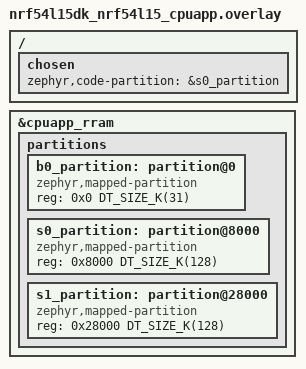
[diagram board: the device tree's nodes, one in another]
/*
 * Copyright (c) 2026 Nordic Semiconductor ASA
 *
 * SPDX-License-Identifier: LicenseRef-Nordic-5-Clause
 */

&cpuapp_rram {
	/delete-node/ partitions;

	partitions {
		ranges;
		#address-cells = <1>;
		#size-cells = <1>;

		/* In this configuration NSIBI protects itself only.
		 * On nrf54l15 it can lock up to 31k of continuous regions.
		 * That is why the partition is sized at 31k.
		 * Alignment of next partition still set at the 4k boundaries,
		 * as that is the alignemnt Flash API will report for RRAM.
		 */
		b0_partition: partition@0 {
			compatible = "zephyr,mapped-partition";
			reg = <0x0 DT_SIZE_K(31)>;
		};

		s0_partition: partition@8000 {
			compatible = "zephyr,mapped-partition";
			reg = <0x8000 DT_SIZE_K(128)>;
		};

		s1_partition: partition@28000 {
			compatible = "zephyr,mapped-partition";
			reg = <0x28000 DT_SIZE_K(128)>;
		};
	};
};

/ {
	chosen {
		zephyr,code-partition = &s0_partition;
	};
};
